VERSION "1.0"

NS_ :

BS_:

BU_: VCU ADAS AEB

BO_ 256 VCU_Status: 8 VCU
 SG_ VehicleSpeed : 0|16@1+ (0.01,0) [0|250] "km/h" ADAS,AEB
 SG_ YawRate : 16|16@1- (0.01,0) [-100|100] "deg/s" ADAS,AEB

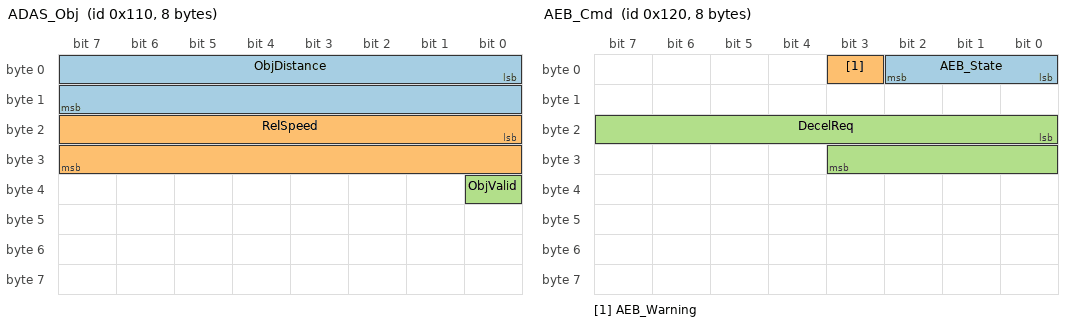
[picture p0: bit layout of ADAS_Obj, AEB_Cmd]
BO_ 272 ADAS_Obj: 8 ADAS
 SG_ ObjDistance : 0|16@1+ (0.01,0) [0|300] "m" AEB
 SG_ RelSpeed : 16|16@1- (0.01,0) [-100|100] "m/s" AEB
 SG_ ObjValid : 32|1@1+ (1,0) [0|1] "" AEB

BO_ 288 AEB_Cmd: 8 AEB
 SG_ AEB_State : 0|3@1+ (1,0) [0|7] "" VCU,ADAS
 SG_ AEB_Warning : 3|1@1+ (1,0) [0|1] "" VCU,ADAS
 SG_ DecelReq : 16|12@1- (0.01,0) [-12|0] "m/s2" VCU,ADAS

CM_ BO_ 256 "Vehicle status published by VCU, 10 ms cycle";
CM_ BO_ 272 "Perception object published by ADAS, 20 ms cycle";
CM_ BO_ 288 "AEB command published by AEB ECU, 10 ms cycle";

CM_ SG_ 256 VehicleSpeed "Own vehicle speed";
CM_ SG_ 256 YawRate "Yaw rate, negative = left turn";
CM_ SG_ 272 ObjDistance "Longitudinal gap to leading object";
CM_ SG_ 272 RelSpeed "Relative speed, negative = closing in";
CM_ SG_ 272 ObjValid "1 = object detected and tracked";
CM_ SG_ 288 AEB_State "0=OFF 1=ARMED 2=ACTIVE 3=FAULT";
CM_ SG_ 288 AEB_Warning "Forward collision warning, 1 = active";
CM_ SG_ 288 DecelReq "Requested deceleration, negative = braking";

VAL_ 288 AEB_State 0 "OFF" 1 "ARMED" 2 "ACTIVE" 3 "FAULT" ;

BA_DEF_ BO_ "GenMsgCycleTime" INT 0 10000;
BA_DEF_DEF_ "GenMsgCycleTime" 0;
BA_ "GenMsgCycleTime" BO_ 256 10;
BA_ "GenMsgCycleTime" BO_ 272 20;
BA_ "GenMsgCycleTime" BO_ 288 10;
